VERSION "1"

NS_ :

BS_:

BU_: Ecu1 Ecu2

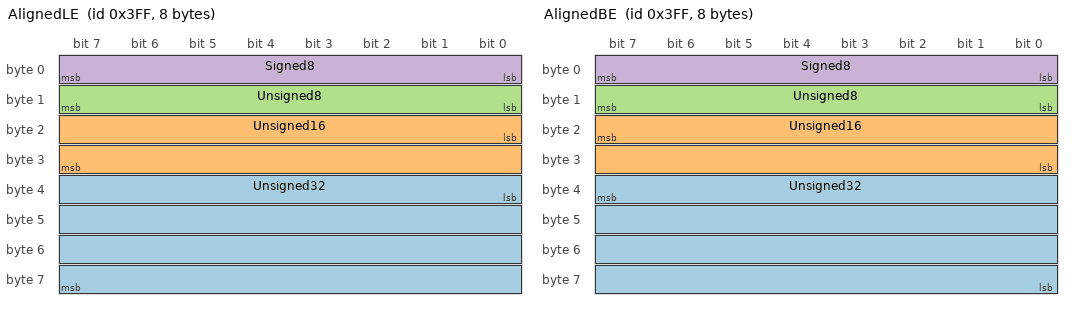
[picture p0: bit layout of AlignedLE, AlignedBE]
BO_ 1023 AlignedLE: 8 Ecu1
 SG_ Unsigned32 : 32|32@1+ (1,0) [0|0] "" Vector__XXX
 SG_ Unsigned16 : 16|16@1+ (1,0) [0|0] "" Vector__XXX
 SG_ Unsigned8 : 8|8@1+ (1,0) [0|0] "" Vector__XXX
 SG_ Signed8 : 0|8@1- (1,0) [0|0] "" Vector__XXX

BO_ 1023 AlignedBE: 8 Ecu1
 SG_ Unsigned32 : 39|32@0+ (1,0) [0|0] "" Vector__XXX
 SG_ Unsigned16 : 23|16@0+ (1,0) [0|0] "" Vector__XXX
 SG_ Unsigned8 : 15|8@0+ (1,0) [0|0] "" Vector__XXX
 SG_ Signed8 : 7|8@0- (1,0) [0|0] "" Vector__XXX

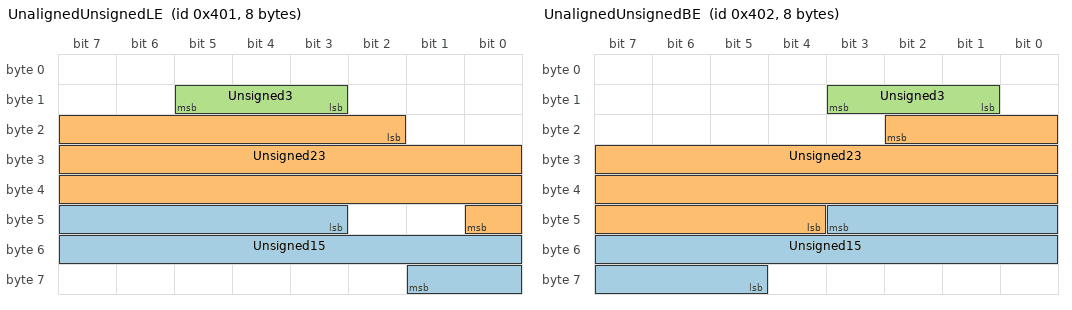
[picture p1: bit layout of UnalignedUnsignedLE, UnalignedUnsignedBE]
BO_ 1025 UnalignedUnsignedLE: 8 Ecu1
 SG_ Unsigned15 : 43|15@1+ (1,0) [0|0] "" Vector__XXX
 SG_ Unsigned23 : 18|23@1+ (1,0) [0|0] "" Vector__XXX
 SG_ Unsigned3 : 11|3@1+ (1,0) [0|0] "" Vector__XXX

BO_ 1026 UnalignedUnsignedBE: 8 Ecu1
 SG_ Unsigned15 : 43|15@0+ (1,0) [0|0] "" Vector__XXX
 SG_ Unsigned23 : 18|23@0+ (1,0) [0|0] "" Vector__XXX
 SG_ Unsigned3 : 11|3@0+ (1,0) [0|0] "" Vector__XXX

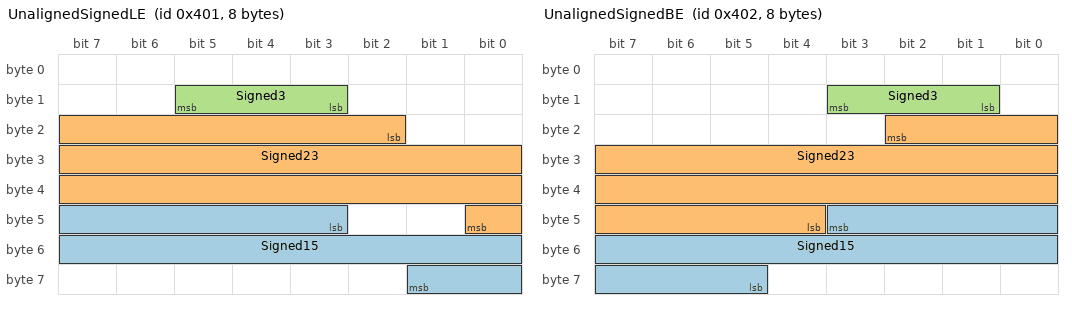
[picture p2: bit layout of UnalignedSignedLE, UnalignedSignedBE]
BO_ 1025 UnalignedSignedLE: 8 Ecu1
 SG_ Signed15 : 43|15@1- (1,0) [0|0] "" Vector__XXX
 SG_ Signed23 : 18|23@1- (1,0) [0|0] "" Vector__XXX
 SG_ Signed3 : 11|3@1- (1,0) [0|0] "" Vector__XXX

BO_ 1026 UnalignedSignedBE: 8 Ecu1
 SG_ Signed15 : 43|15@0- (1,0) [0|0] "" Vector__XXX
 SG_ Signed23 : 18|23@0- (1,0) [0|0] "" Vector__XXX
 SG_ Signed3 : 11|3@0- (1,0) [0|0] "" Vector__XXX

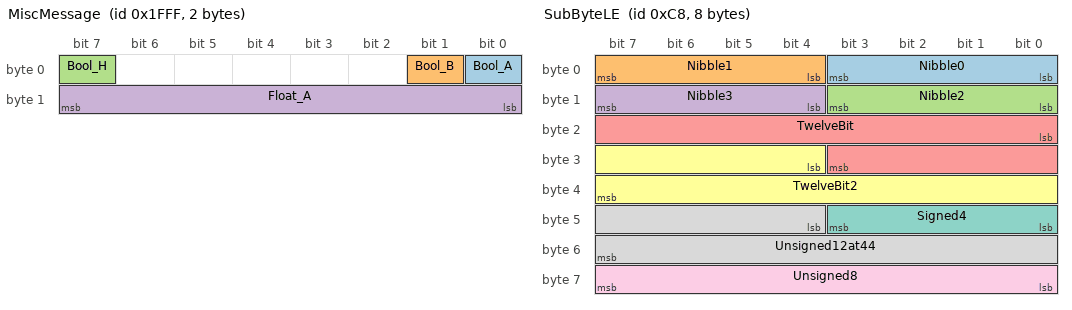
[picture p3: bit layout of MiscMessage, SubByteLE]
BO_ 8191 MiscMessage: 2 Ecu2
 SG_ Bool_A : 0|1@1+ (1,0) [0|1] "" Vector__XXX
 SG_ Bool_B : 1|1@1+ (1,0) [0|1] "" Vector__XXX
 SG_ Bool_H : 7|1@1+ (1,0) [0|1] "" Vector__XXX
 SG_ Float_A : 8|8@1+ (0.5,0.25) [0|0] "" Vector__XXX

BO_ 64 SixtyFourBitLE: 8 Ecu2
 SG_ SixtyFour : 0|64@1+ (1,0) [0|0] "" Vector_XXX

BO_ 65 SixtyFourBitBE: 8 Ecu2
 SG_ SixtyFour : 7|64@0+ (1,0) [0|0] "" Vector_XXX

BO_ 66 SixtyFourBitSigned: 8 Ecu2
 SG_ SixtyFour : 0|64@1- (1,0) [0|0] "" Vector_XXX

BO_ 128 GroupData1: 8 Ecu1
 SG_ ValueA : 0|32@1+ (1,0) [0|0] "" Vector__XXX
 SG_ ValueB : 32|32@1+ (1,0) [0|0] "" Vector__XXX

BO_ 129 GroupData2: 8 Ecu1
 SG_ ValueA : 0|32@1+ (1,0) [0|0] "" Vector__XXX
 SG_ ValueB : 32|32@1+ (1,0) [0|0] "" Vector__XXX

BO_ 130 GroupData3: 8 Ecu1
 SG_ ValueA : 0|32@1+ (1,0) [0|0] "" Vector__XXX
 SG_ ValueB : 32|32@1+ (1,0) [0|0] "" Vector__XXX

BO_ 200 SubByteLE: 8 Ecu1
 SG_ Nibble0 : 0|4@1+ (1,0) [0|15] "" Vector__XXX
 SG_ Nibble1 : 4|4@1+ (1,0) [0|15] "" Vector__XXX
 SG_ Nibble2 : 8|4@1+ (1,0) [0|15] "" Vector__XXX
 SG_ Nibble3 : 12|4@1+ (1,0) [0|15] "" Vector__XXX
 SG_ TwelveBit : 16|12@1+ (1,0) [0|4095] "" Vector__XXX
 SG_ TwelveBit2 : 28|12@1+ (1,0) [0|4095] "" Vector__XXX
 SG_ Signed4 : 40|4@1- (1,0) [0|0] "" Vector__XXX
 SG_ Unsigned12at44 : 44|12@1+ (1,0) [0|4095] "" Vector__XXX
 SG_ Unsigned8 : 56|8@1+ (1,0) [0|255] "" Vector__XXX

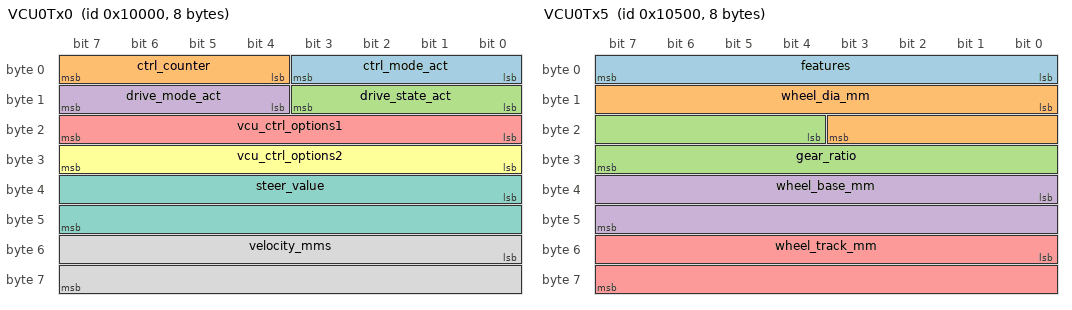
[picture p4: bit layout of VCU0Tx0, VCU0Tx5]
BO_ 65536 VCU0Tx0: 8 VCU0
 SG_ ctrl_mode_act : 0|4@1+ (1,0) [0|15] "MODE" Vector__XXX
 SG_ ctrl_counter : 4|4@1+ (1,0) [0|15] "CNT" Vector__XXX
 SG_ drive_state_act : 8|4@1+ (1,0) [0|15] "STATE" Vector__XXX
 SG_ drive_mode_act : 12|4@1+ (1,0) [0|15] "MODE" Vector__XXX
 SG_ vcu_ctrl_options1 : 16|8@1+ (1,0) [0|255] "OPT1" Vector__XXX
 SG_ vcu_ctrl_options2 : 24|8@1+ (1,0) [0|255] "OPT2" Vector__XXX
 SG_ steer_value : 32|16@1- (1,0) [-32768|32767] "CM" Vector__XXX
 SG_ velocity_mms : 48|16@1- (1,0) [-32768|32767] "MM/S" Vector__XXX

BO_ 66816 VCU0Tx5: 8 VCU0
 SG_ features : 0|8@1+ (1,0) [0|255] "FEAT" Vector__XXX
 SG_ wheel_dia_mm : 8|12@1+ (1,0) [0|4095] "MM" Vector__XXX
 SG_ gear_ratio : 20|12@1+ (1,0) [0|4095] "RATIO" Vector__XXX
 SG_ wheel_base_mm : 32|16@1+ (1,0) [0|65535] "MM" Vector__XXX
 SG_ wheel_track_mm : 48|16@1+ (1,0) [0|65535] "MM" Vector__XXX

BA_DEF_DEF_  "GenMsgCycleTime" 0;

BA_ "GenMsgCycleTime" BO_ 8191 100;
BA_ "GenMsgCycleTime" BO_ 66 2000;
